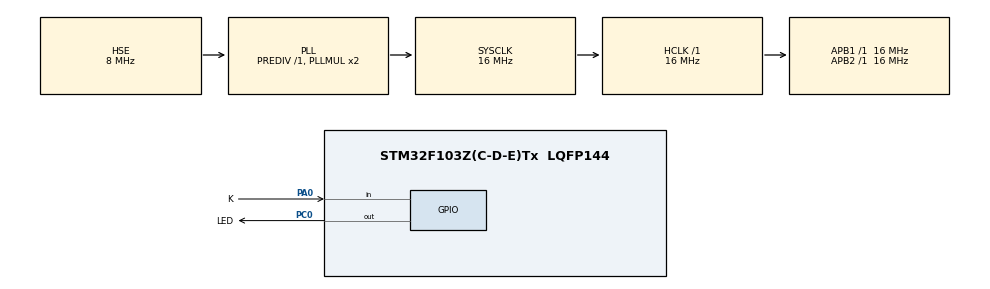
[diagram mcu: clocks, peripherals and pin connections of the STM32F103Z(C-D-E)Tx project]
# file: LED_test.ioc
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Mcu.Family=STM32F1
Mcu.Name=STM32F103Z(C-D-E)Tx
Mcu.Package=LQFP144
NVIC.PriorityGroup=NVIC_PRIORITYGROUP_4
OSC_IN.Mode=HSE-External-Oscillator
OSC_IN.Signal=RCC_OSC_IN
OSC_OUT.Mode=HSE-External-Oscillator
OSC_OUT.Signal=RCC_OSC_OUT
PA0-WKUP.GPIO_Label=K
PA0-WKUP.GPIO_PuPd=GPIO_PULLUP
PA0-WKUP.Signal=GPIO_Input
PA13.Mode=JTAG_4_pins
PA13.Signal=SYS_JTMS-SWDIO
PA14.Mode=JTAG_4_pins
PA14.Signal=SYS_JTCK-SWCLK
PA15.Mode=JTAG_4_pins
PA15.Signal=SYS_JTDI
PB3.Mode=JTAG_4_pins
PB3.Signal=SYS_JTDO-TRACESWO
PC0.GPIO_Label=LED
PC0.GPIO_PuPd=GPIO_NOPULL
PC0.Signal=GPIO_Output
ProjectManager.HeapSize=0x200
ProjectManager.StackSize=0x400
ProjectManager.TargetToolchain=MDK-ARM V5.32
RCC.AHBFreq_Value=16000000
RCC.APB1Freq_Value=16000000
RCC.APB1TimFreq_Value=16000000
RCC.APB2Freq_Value=16000000
RCC.APB2TimFreq_Value=16000000
RCC.EnbaleCSS=true
RCC.HCLKFreq_Value=16000000
RCC.PLLSourceVirtual=RCC_PLLSOURCE_HSE
RCC.SYSCLKFreq_VALUE=16000000
RCC.SYSCLKSource=RCC_SYSCLKSOURCE_PLLCLK
RCC.USBFreq_Value=16000000
board=custom

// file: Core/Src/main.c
/* USER CODE BEGIN Header */
/**
  ******************************************************************************
  * @file           : main.c
  * @brief          : Main program body
  ******************************************************************************
  * @attention
  *
  * Copyright (c) 2024 STMicroelectronics.
  * All rights reserved.
  *
  * This software is licensed under terms that can be found in the LICENSE file
  * in the root directory of this software component.
  * If no LICENSE file comes with this software, it is provided AS-IS.
  *
  ******************************************************************************
  */
/* USER CODE END Header */
#include "main.h"

/* USER CODE BEGIN PD */
#define BounceTimeMS 200
/* USER CODE END PD */

/* USER CODE BEGIN PV */
volatile int lastTimeKeyPressed;
/* USER CODE END PV */

void SystemClock_Config(void);
static void MX_GPIO_Init(void);
/* USER CODE BEGIN PFP */
uint8_t bounceTimePassed();
/* USER CODE END PFP */

int main(void)
{

  /* MCU Configuration--------------------------------------------------------*/

  /* Reset of all peripherals, Initializes the Flash interface and the Systick. */
  HAL_Init();

  /* Configure the system clock */
  SystemClock_Config();

  /* Initialize all configured peripherals */
  MX_GPIO_Init();

  /* Infinite loop */
  while (1)
  {
		/*while(!HAL_GPIO_ReadPin(K_GPIO_Port, K_Pin)){
			HAL_GPIO_TogglePin(LED_GPIO_Port, LED_Pin);
			HAL_Delay(500);
		}*/
		/*
		if(!HAL_GPIO_ReadPin(K_GPIO_Port, K_Pin))
			HAL_GPIO_WritePin(LED_GPIO_Port,LED_Pin, GPIO_PIN_SET);
		else
			HAL_GPIO_WritePin(LED_GPIO_Port,LED_Pin, GPIO_PIN_RESET);
		*/
		//HAL_GPIO_WritePin(LED_GPIO_Port,LED_Pin, (!HAL_GPIO_ReadPin(K_GPIO_Port, K_Pin)));

		if(!HAL_GPIO_ReadPin(K_GPIO_Port, K_Pin)){
			HAL_Delay(20);
			if(!HAL_GPIO_ReadPin(K_GPIO_Port, K_Pin))
				HAL_GPIO_WritePin(LED_GPIO_Port, LED_Pin, GPIO_PIN_SET);
			while(!HAL_GPIO_ReadPin(K_GPIO_Port, K_Pin)) HAL_Delay(20);
			HAL_Delay(20);
		}

		if(HAL_GPIO_ReadPin(K_GPIO_Port, K_Pin)){
			HAL_Delay(20);
			if(HAL_GPIO_ReadPin(K_GPIO_Port, K_Pin))
				HAL_GPIO_WritePin(LED_GPIO_Port, LED_Pin, GPIO_PIN_RESET);
			while(HAL_GPIO_ReadPin(K_GPIO_Port, K_Pin)) HAL_Delay(20);
			HAL_Delay(20);
		}

  }
}

void SystemClock_Config(void)
{
  RCC_OscInitTypeDef RCC_OscInitStruct = {0};
  RCC_ClkInitTypeDef RCC_ClkInitStruct = {0};

  /** Initializes the RCC Oscillators according to the specified parameters
  * in the RCC_OscInitTypeDef structure.
  */
  RCC_OscInitStruct.OscillatorType = RCC_OSCILLATORTYPE_HSE;
  RCC_OscInitStruct.HSEState = RCC_HSE_ON;
  RCC_OscInitStruct.HSEPredivValue = RCC_HSE_PREDIV_DIV1;
  RCC_OscInitStruct.HSIState = RCC_HSI_ON;
  RCC_OscInitStruct.PLL.PLLState = RCC_PLL_ON;
  RCC_OscInitStruct.PLL.PLLSource = RCC_PLLSOURCE_HSE;
  RCC_OscInitStruct.PLL.PLLMUL = RCC_PLL_MUL2;
  if (HAL_RCC_OscConfig(&RCC_OscInitStruct) != HAL_OK)
  {
    Error_Handler();
  }

  /** Initializes the CPU, AHB and APB buses clocks
  */
  RCC_ClkInitStruct.ClockType = RCC_CLOCKTYPE_HCLK|RCC_CLOCKTYPE_SYSCLK
                              |RCC_CLOCKTYPE_PCLK1|RCC_CLOCKTYPE_PCLK2;
  RCC_ClkInitStruct.SYSCLKSource = RCC_SYSCLKSOURCE_PLLCLK;
  RCC_ClkInitStruct.AHBCLKDivider = RCC_SYSCLK_DIV1;
  RCC_ClkInitStruct.APB1CLKDivider = RCC_HCLK_DIV1;
  RCC_ClkInitStruct.APB2CLKDivider = RCC_HCLK_DIV1;

  if (HAL_RCC_ClockConfig(&RCC_ClkInitStruct, FLASH_LATENCY_0) != HAL_OK)
  {
    Error_Handler();
  }

  /** Enables the Clock Security System
  */
  HAL_RCC_EnableCSS();
}

static void MX_GPIO_Init(void)
{
  GPIO_InitTypeDef GPIO_InitStruct = {0};

  /* GPIO Ports Clock Enable */
  __HAL_RCC_GPIOC_CLK_ENABLE();
  __HAL_RCC_GPIOA_CLK_ENABLE();

  /*Configure GPIO pin Output Level */
  HAL_GPIO_WritePin(LED_GPIO_Port, LED_Pin, GPIO_PIN_RESET);

  /*Configure GPIO pin : LED_Pin */
  GPIO_InitStruct.Pin = LED_Pin;
  GPIO_InitStruct.Mode = GPIO_MODE_OUTPUT_PP;
  GPIO_InitStruct.Pull = GPIO_NOPULL;
  GPIO_InitStruct.Speed = GPIO_SPEED_FREQ_LOW;
  HAL_GPIO_Init(LED_GPIO_Port, &GPIO_InitStruct);

  /*Configure GPIO pin : K_Pin */
  GPIO_InitStruct.Pin = K_Pin;
  GPIO_InitStruct.Mode = GPIO_MODE_INPUT;
  GPIO_InitStruct.Pull = GPIO_PULLUP;
  HAL_GPIO_Init(K_GPIO_Port, &GPIO_InitStruct);

}

void Error_Handler(void)
{
  __disable_irq();
  while (1)
  {
  }
}

uint8_t bounceTimePassed(){
	int currentTime = HAL_GetTick();
	if( currentTime - lastTimeKeyPressed > BounceTimeMS)
		return 1;
	else
		return 0;
}
